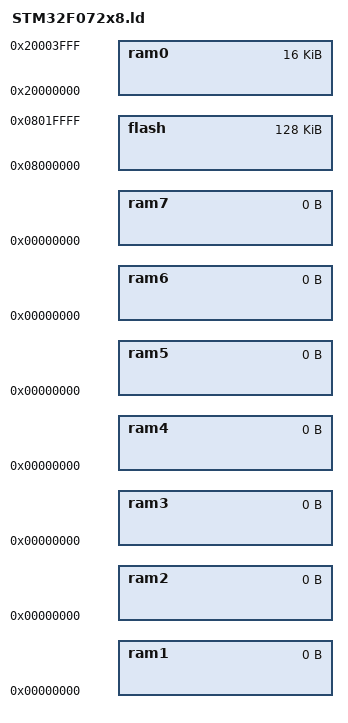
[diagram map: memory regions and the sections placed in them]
/*
KL LD file, based on Chibios v16.1.2. 
20160126
*/

 /* Put it here instead of Makefile */
__main_stack_size__     = 0x0400; 
__process_stack_size__  = 0x0400;

/*
 * STM32F072x8 memory setup.
 */
MEMORY
{
    flash : org = 0x08000000, len = 128k
    ram0  : org = 0x20000000, len = 16k
    ram1  : org = 0x00000000, len = 0
    ram2  : org = 0x00000000, len = 0
    ram3  : org = 0x00000000, len = 0
    ram4  : org = 0x00000000, len = 0
    ram5  : org = 0x00000000, len = 0
    ram6  : org = 0x00000000, len = 0
    ram7  : org = 0x00000000, len = 0
}

/* RAM region to be used for Main stack. This stack accommodates the processing
   of all exceptions and interrupts*/
REGION_ALIAS("MAIN_STACK_RAM", ram0);

/* RAM region to be used for the process stack. This is the stack used by
   the main() function.*/
REGION_ALIAS("PROCESS_STACK_RAM", ram0);

/* RAM region to be used for data segment.*/
REGION_ALIAS("DATA_RAM", ram0);

/* RAM region to be used for BSS segment.*/
REGION_ALIAS("BSS_RAM", ram0);

/* RAM region to be used for the default heap.*/
REGION_ALIAS("HEAP_RAM", ram0);

INCLUDE ../rules.ld
